# ionuc505 register map
Registers are 32-bit, access not given, no defined reset value unless marked. A register's access mark holds for its fields unless they carry their own. Addresses are absolute; registers are grouped by the start of their names; [hi:lo] are bit positions; {n}, {i} and the like mark numbered series; 'fields as' and 'values as' point back to an identical list.

## USBD
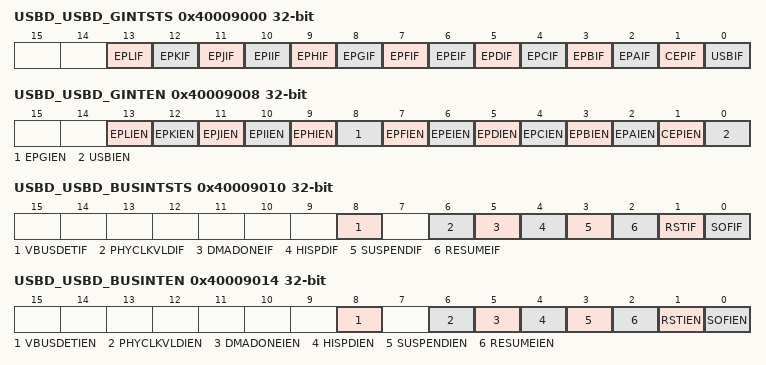
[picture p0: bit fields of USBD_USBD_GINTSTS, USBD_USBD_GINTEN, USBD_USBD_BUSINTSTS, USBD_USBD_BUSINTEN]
0x40009000 USBD_USBD_GINTSTS
  [13] EPLIF, [12] EPKIF, [11] EPJIF, [10] EPIIF, [9] EPHIF, [8] EPGIF, [7] EPFIF, [6] EPEIF, [5] EPDIF, [4] EPCIF, [3] EPBIF, [2] EPAIF, [1] CEPIF, [0] USBIF
0x40009008 USBD_USBD_GINTEN
  [13] EPLIEN, [12] EPKIEN, [11] EPJIEN, [10] EPIIEN, [9] EPHIEN, [8] EPGIEN, [7] EPFIEN, [6] EPEIEN, [5] EPDIEN, [4] EPCIEN, [3] EPBIEN, [2] EPAIEN, [1] CEPIEN, [0] USBIEN
0x40009010 USBD_USBD_BUSINTSTS
  [8] VBUSDETIF, [6] PHYCLKVLDIF, [5] DMADONEIF, [4] HISPDIF, [3] SUSPENDIF, [2] RESUMEIF, [1] RSTIF, [0] SOFIF
0x40009014 USBD_USBD_BUSINTEN
  [8] VBUSDETIEN, [6] PHYCLKVLDIEN, [5] DMADONEIEN, [4] HISPDIEN, [3] SUSPENDIEN, [2] RESUMEIEN, [1] RSTIEN, [0] SOFIEN
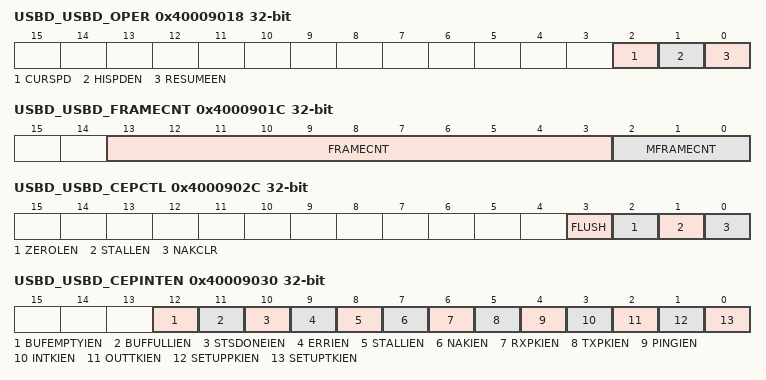
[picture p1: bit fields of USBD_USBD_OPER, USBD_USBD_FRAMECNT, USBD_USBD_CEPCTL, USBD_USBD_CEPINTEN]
0x40009018 USBD_USBD_OPER
  [2] CURSPD, [1] HISPDEN, [0] RESUMEEN
0x4000901C USBD_USBD_FRAMECNT
  [13:3] FRAMECNT, [2:0] MFRAMECNT
0x40009020 USBD_USBD_FADDR
  [6:0] FADDR
0x40009024 USBD_USBD_TEST
  [2:0] TESTMODE
0x40009028 USBD_USBD_CEPDAT
0x4000902C USBD_USBD_CEPCTL
  [3] FLUSH, [2] ZEROLEN, [1] STALLEN, [0] NAKCLR
0x40009030 USBD_USBD_CEPINTEN
  [12] BUFEMPTYIEN, [11] BUFFULLIEN, [10] STSDONEIEN, [9] ERRIEN, [8] STALLIEN, [7] NAKIEN, [6] RXPKIEN, [5] TXPKIEN, [4] PINGIEN, [3] INTKIEN, [2] OUTTKIEN, [1] SETUPPKIEN, [0] SETUPTKIEN
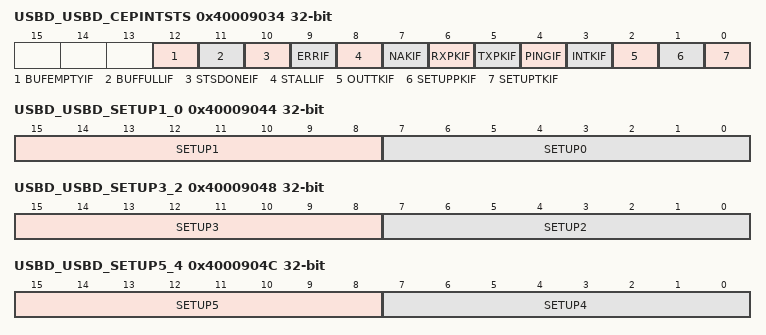
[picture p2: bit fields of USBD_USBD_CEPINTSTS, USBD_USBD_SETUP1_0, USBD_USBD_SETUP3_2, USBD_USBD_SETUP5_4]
0x40009034 USBD_USBD_CEPINTSTS
  [12] BUFEMPTYIF, [11] BUFFULLIF, [10] STSDONEIF, [9] ERRIF, [8] STALLIF, [7] NAKIF, [6] RXPKIF, [5] TXPKIF, [4] PINGIF, [3] INTKIF, [2] OUTTKIF, [1] SETUPPKIF, [0] SETUPTKIF
0x40009038 USBD_USBD_CEPTXCNT
  [7:0] TXCNT
0x4000903C USBD_USBD_CEPRXCNT
  [7:0] RXCNT
0x40009040 USBD_USBD_CEPDATCNT
  [15:0] DATCNT
0x40009044 USBD_USBD_SETUP1_0
  [15:8] SETUP1, [7:0] SETUP0
0x40009048 USBD_USBD_SETUP3_2
  [15:8] SETUP3, [7:0] SETUP2
0x4000904C USBD_USBD_SETUP5_4
  [15:8] SETUP5, [7:0] SETUP4
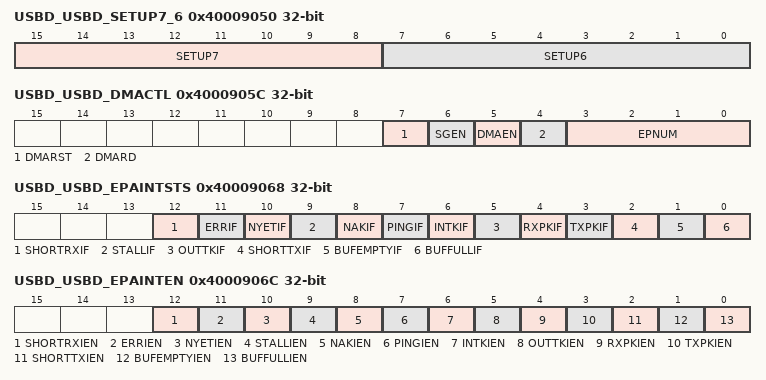
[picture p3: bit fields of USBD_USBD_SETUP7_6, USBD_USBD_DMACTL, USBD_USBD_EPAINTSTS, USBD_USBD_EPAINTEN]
0x40009050 USBD_USBD_SETUP7_6
  [15:8] SETUP7, [7:0] SETUP6
0x40009054 USBD_USBD_CEPBUFSTART
  [11:0] SADDR
0x40009058 USBD_USBD_CEPBUFEND
  [11:0] EADDR
0x4000905C USBD_USBD_DMACTL
  [7] DMARST, [6] SGEN, [5] DMAEN, [4] DMARD, [3:0] EPNUM
0x40009060 USBD_USBD_DMACNT
  [19:0] DMACNT
0x40009064 USBD_USBD_EPADAT
0x40009068 USBD_USBD_EPAINTSTS
  [12] SHORTRXIF, [11] ERRIF, [10] NYETIF, [9] STALLIF, [8] NAKIF, [7] PINGIF, [6] INTKIF, [5] OUTTKIF, [4] RXPKIF, [3] TXPKIF, [2] SHORTTXIF, [1] BUFEMPTYIF, [0] BUFFULLIF
0x4000906C USBD_USBD_EPAINTEN
  [12] SHORTRXIEN, [11] ERRIEN, [10] NYETIEN, [9] STALLIEN, [8] NAKIEN, [7] PINGIEN, [6] INTKIEN, [5] OUTTKIEN, [4] RXPKIEN, [3] TXPKIEN, [2] SHORTTXIEN, [1] BUFEMPTYIEN, [0] BUFFULLIEN
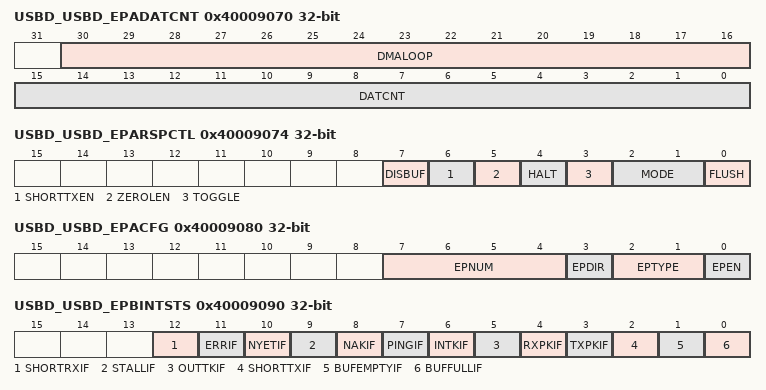
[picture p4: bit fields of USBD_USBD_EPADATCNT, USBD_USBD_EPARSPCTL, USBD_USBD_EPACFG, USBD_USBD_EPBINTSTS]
0x40009070 USBD_USBD_EPADATCNT
  [30:16] DMALOOP, [15:0] DATCNT
0x40009074 USBD_USBD_EPARSPCTL
  [7] DISBUF, [6] SHORTTXEN, [5] ZEROLEN, [4] HALT, [3] TOGGLE, [2:1] MODE, [0] FLUSH
0x40009078 USBD_USBD_EPAMPS
  [10:0] EPMPS
0x4000907C USBD_USBD_EPATXCNT
  [10:0] TXCNT
0x40009080 USBD_USBD_EPACFG
  [7:4] EPNUM, [3] EPDIR, [2:1] EPTYPE, [0] EPEN
0x40009084 USBD_USBD_EPABUFSTART
  [11:0] SADDR
0x40009088 USBD_USBD_EPABUFEND
  [11:0] EADDR
0x4000908C USBD_USBD_EPBDAT
0x40009090 USBD_USBD_EPBINTSTS
  fields as USBD_USBD_EPAINTSTS
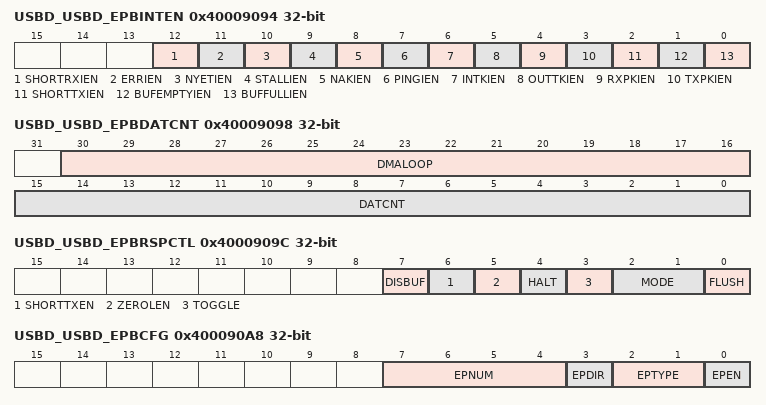
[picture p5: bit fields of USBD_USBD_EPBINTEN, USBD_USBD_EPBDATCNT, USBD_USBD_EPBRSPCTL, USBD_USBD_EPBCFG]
0x40009094 USBD_USBD_EPBINTEN
  fields as USBD_USBD_EPAINTEN
0x40009098 USBD_USBD_EPBDATCNT
  [30:16] DMALOOP, [15:0] DATCNT
0x4000909C USBD_USBD_EPBRSPCTL
  fields as USBD_USBD_EPARSPCTL
0x400090A0 USBD_USBD_EPBMPS
  [10:0] EPMPS
0x400090A4 USBD_USBD_EPBTXCNT
  [10:0] TXCNT
0x400090A8 USBD_USBD_EPBCFG
  [7:4] EPNUM, [3] EPDIR, [2:1] EPTYPE, [0] EPEN
0x400090AC USBD_USBD_EPBBUFSTART
  [11:0] SADDR
0x400090B0 USBD_USBD_EPBBUFEND
  [11:0] EADDR
0x400090B4 USBD_USBD_EPCDAT
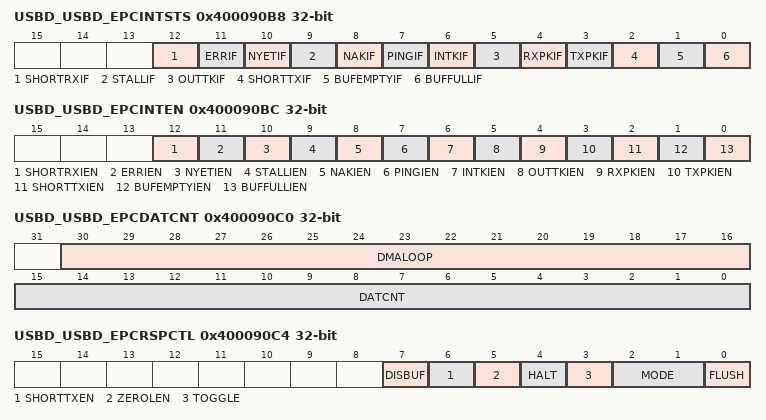
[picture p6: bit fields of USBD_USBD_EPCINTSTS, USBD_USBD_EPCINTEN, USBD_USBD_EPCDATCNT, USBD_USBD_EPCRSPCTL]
0x400090B8 USBD_USBD_EPCINTSTS
  fields as USBD_USBD_EPAINTSTS
0x400090BC USBD_USBD_EPCINTEN
  fields as USBD_USBD_EPAINTEN
0x400090C0 USBD_USBD_EPCDATCNT
  [30:16] DMALOOP, [15:0] DATCNT
0x400090C4 USBD_USBD_EPCRSPCTL
  fields as USBD_USBD_EPARSPCTL
0x400090C8 USBD_USBD_EPCMPS
  [10:0] EPMPS
0x400090CC USBD_USBD_EPCTXCNT
  [10:0] TXCNT
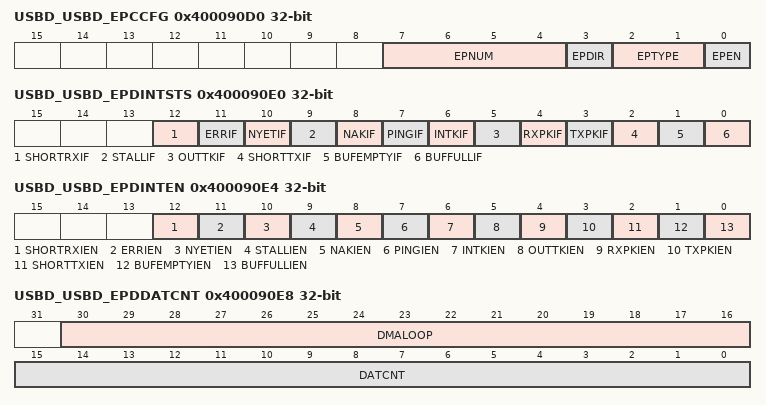
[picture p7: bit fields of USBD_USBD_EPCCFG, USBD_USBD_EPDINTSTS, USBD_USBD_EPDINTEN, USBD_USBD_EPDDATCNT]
0x400090D0 USBD_USBD_EPCCFG
  [7:4] EPNUM, [3] EPDIR, [2:1] EPTYPE, [0] EPEN
0x400090D4 USBD_USBD_EPCBUFSTART
  [11:0] SADDR
0x400090D8 USBD_USBD_EPCBUFEND
  [11:0] EADDR
0x400090DC USBD_USBD_EPDDAT
0x400090E0 USBD_USBD_EPDINTSTS
  fields as USBD_USBD_EPAINTSTS
0x400090E4 USBD_USBD_EPDINTEN
  fields as USBD_USBD_EPAINTEN
0x400090E8 USBD_USBD_EPDDATCNT
  [30:16] DMALOOP, [15:0] DATCNT
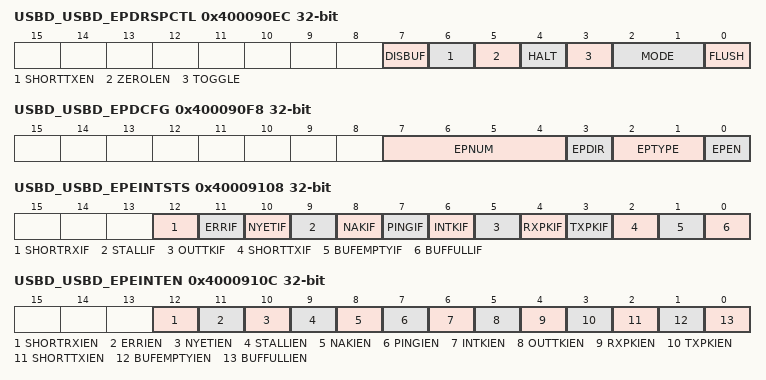
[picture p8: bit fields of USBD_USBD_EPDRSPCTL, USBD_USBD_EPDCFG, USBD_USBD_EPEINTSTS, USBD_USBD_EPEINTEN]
0x400090EC USBD_USBD_EPDRSPCTL
  fields as USBD_USBD_EPARSPCTL
0x400090F0 USBD_USBD_EPDMPS
  [10:0] EPMPS
0x400090F4 USBD_USBD_EPDTXCNT
  [10:0] TXCNT
0x400090F8 USBD_USBD_EPDCFG
  [7:4] EPNUM, [3] EPDIR, [2:1] EPTYPE, [0] EPEN
0x400090FC USBD_USBD_EPDBUFSTART
  [11:0] SADDR
0x40009100 USBD_USBD_EPDBUFEND
  [11:0] EADDR
0x40009104 USBD_USBD_EPEDAT
0x40009108 USBD_USBD_EPEINTSTS
  fields as USBD_USBD_EPAINTSTS
0x4000910C USBD_USBD_EPEINTEN
  fields as USBD_USBD_EPAINTEN
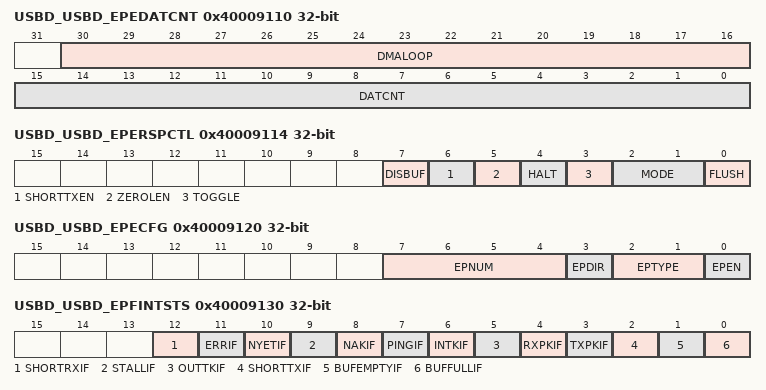
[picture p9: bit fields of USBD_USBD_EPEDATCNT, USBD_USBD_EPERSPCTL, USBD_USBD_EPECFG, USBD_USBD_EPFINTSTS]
0x40009110 USBD_USBD_EPEDATCNT
  [30:16] DMALOOP, [15:0] DATCNT
0x40009114 USBD_USBD_EPERSPCTL
  fields as USBD_USBD_EPARSPCTL
0x40009118 USBD_USBD_EPEMPS
  [10:0] EPMPS
0x4000911C USBD_USBD_EPETXCNT
  [10:0] TXCNT
0x40009120 USBD_USBD_EPECFG
  [7:4] EPNUM, [3] EPDIR, [2:1] EPTYPE, [0] EPEN
0x40009124 USBD_USBD_EPEBUFSTART
  [11:0] SADDR
0x40009128 USBD_USBD_EPEBUFEND
  [11:0] EADDR
0x4000912C USBD_USBD_EPFDAT
0x40009130 USBD_USBD_EPFINTSTS
  fields as USBD_USBD_EPAINTSTS
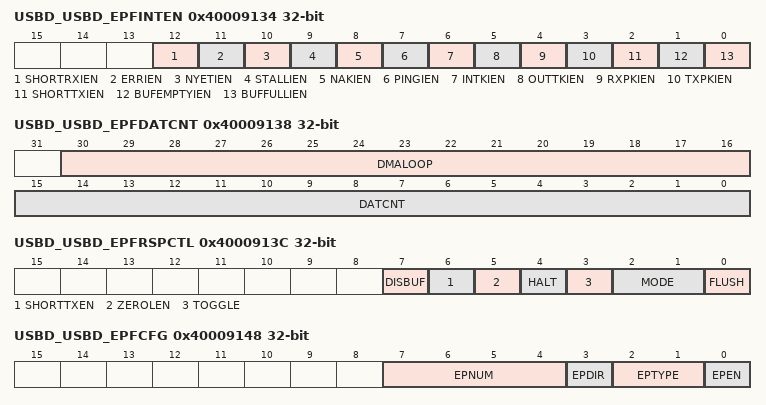
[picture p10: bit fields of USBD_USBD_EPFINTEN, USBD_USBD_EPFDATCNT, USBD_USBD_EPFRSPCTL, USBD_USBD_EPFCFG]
0x40009134 USBD_USBD_EPFINTEN
  fields as USBD_USBD_EPAINTEN
0x40009138 USBD_USBD_EPFDATCNT
  [30:16] DMALOOP, [15:0] DATCNT
0x4000913C USBD_USBD_EPFRSPCTL
  fields as USBD_USBD_EPARSPCTL
0x40009140 USBD_USBD_EPFMPS
  [10:0] EPMPS
0x40009144 USBD_USBD_EPFTXCNT
  [10:0] TXCNT
0x40009148 USBD_USBD_EPFCFG
  [7:4] EPNUM, [3] EPDIR, [2:1] EPTYPE, [0] EPEN
0x4000914C USBD_USBD_EPFBUFSTART
  [11:0] SADDR
0x40009150 USBD_USBD_EPFBUFEND
  [11:0] EADDR
0x40009154 USBD_USBD_EPGDAT
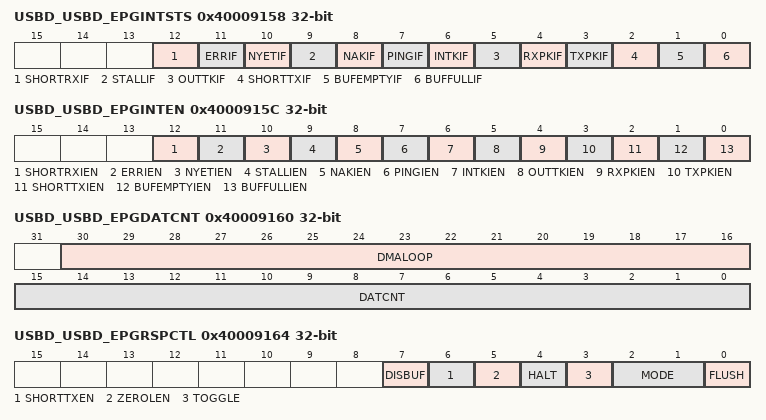
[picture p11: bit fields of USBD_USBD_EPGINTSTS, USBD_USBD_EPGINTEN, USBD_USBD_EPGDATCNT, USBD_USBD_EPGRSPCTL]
0x40009158 USBD_USBD_EPGINTSTS
  fields as USBD_USBD_EPAINTSTS
0x4000915C USBD_USBD_EPGINTEN
  fields as USBD_USBD_EPAINTEN
0x40009160 USBD_USBD_EPGDATCNT
  [30:16] DMALOOP, [15:0] DATCNT
0x40009164 USBD_USBD_EPGRSPCTL
  fields as USBD_USBD_EPARSPCTL
0x40009168 USBD_USBD_EPGMPS
  [10:0] EPMPS
0x4000916C USBD_USBD_EPGTXCNT
  [10:0] TXCNT
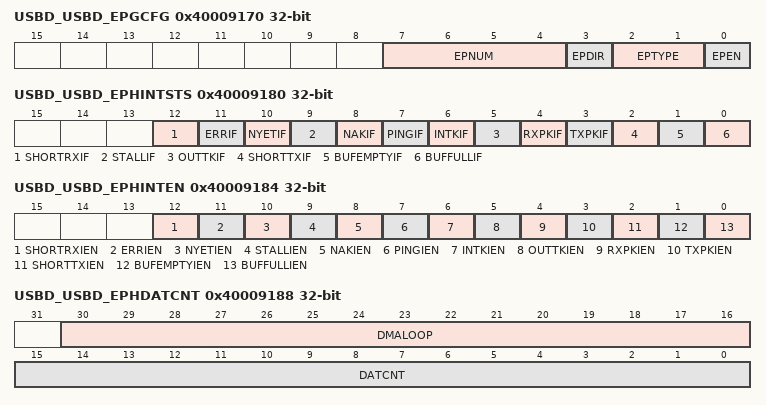
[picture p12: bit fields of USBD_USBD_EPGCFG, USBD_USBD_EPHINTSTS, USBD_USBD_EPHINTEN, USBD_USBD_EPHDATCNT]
0x40009170 USBD_USBD_EPGCFG
  [7:4] EPNUM, [3] EPDIR, [2:1] EPTYPE, [0] EPEN
0x40009174 USBD_USBD_EPGBUFSTART
  [11:0] SADDR
0x40009178 USBD_USBD_EPGBUFEND
  [11:0] EADDR
0x4000917C USBD_USBD_EPHDAT
0x40009180 USBD_USBD_EPHINTSTS
  fields as USBD_USBD_EPAINTSTS
0x40009184 USBD_USBD_EPHINTEN
  fields as USBD_USBD_EPAINTEN
0x40009188 USBD_USBD_EPHDATCNT
  [30:16] DMALOOP, [15:0] DATCNT
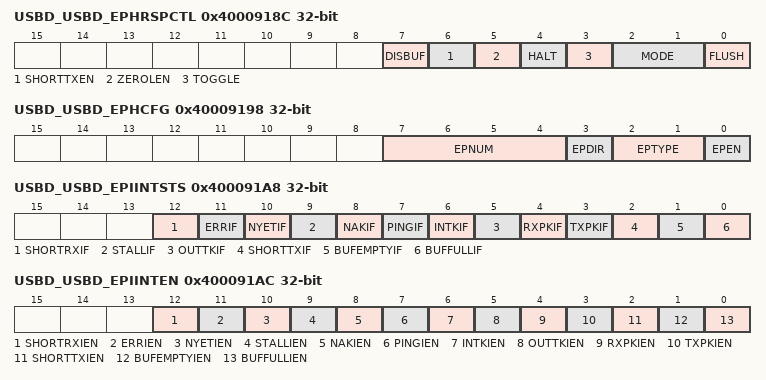
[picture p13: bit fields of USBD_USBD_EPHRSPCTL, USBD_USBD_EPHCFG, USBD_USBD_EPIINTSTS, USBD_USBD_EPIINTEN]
0x4000918C USBD_USBD_EPHRSPCTL
  fields as USBD_USBD_EPARSPCTL
0x40009190 USBD_USBD_EPHMPS
  [10:0] EPMPS
0x40009194 USBD_USBD_EPHTXCNT
  [10:0] TXCNT
0x40009198 USBD_USBD_EPHCFG
  [7:4] EPNUM, [3] EPDIR, [2:1] EPTYPE, [0] EPEN
0x4000919C USBD_USBD_EPHBUFSTART
  [11:0] SADDR
0x400091A0 USBD_USBD_EPHBUFEND
  [11:0] EADDR
0x400091A4 USBD_USBD_EPIDAT
0x400091A8 USBD_USBD_EPIINTSTS
  fields as USBD_USBD_EPAINTSTS
0x400091AC USBD_USBD_EPIINTEN
  fields as USBD_USBD_EPAINTEN
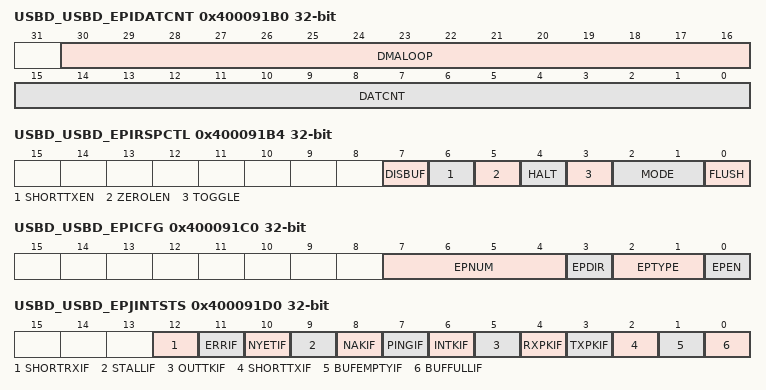
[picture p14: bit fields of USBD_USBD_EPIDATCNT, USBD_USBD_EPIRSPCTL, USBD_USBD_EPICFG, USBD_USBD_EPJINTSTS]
0x400091B0 USBD_USBD_EPIDATCNT
  [30:16] DMALOOP, [15:0] DATCNT
0x400091B4 USBD_USBD_EPIRSPCTL
  fields as USBD_USBD_EPARSPCTL
0x400091B8 USBD_USBD_EPIMPS
  [10:0] EPMPS
0x400091BC USBD_USBD_EPITXCNT
  [10:0] TXCNT
0x400091C0 USBD_USBD_EPICFG
  [7:4] EPNUM, [3] EPDIR, [2:1] EPTYPE, [0] EPEN
0x400091C4 USBD_USBD_EPIBUFSTART
  [11:0] SADDR
0x400091C8 USBD_USBD_EPIBUFEND
  [11:0] EADDR
0x400091CC USBD_USBD_EPJDAT
0x400091D0 USBD_USBD_EPJINTSTS
  fields as USBD_USBD_EPAINTSTS
0x400091D4 USBD_USBD_EPJINTEN
  fields as USBD_USBD_EPAINTEN
0x400091D8 USBD_USBD_EPJDATCNT
  [30:16] DMALOOP, [15:0] DATCNT
0x400091DC USBD_USBD_EPJRSPCTL
  fields as USBD_USBD_EPARSPCTL
0x400091E0 USBD_USBD_EPJMPS
  [10:0] EPMPS
0x400091E4 USBD_USBD_EPJTXCNT
  [10:0] TXCNT
0x400091E8 USBD_USBD_EPJCFG
  [7:4] EPNUM, [3] EPDIR, [2:1] EPTYPE, [0] EPEN
0x400091EC USBD_USBD_EPJBUFSTART
  [11:0] SADDR
0x400091F0 USBD_USBD_EPJBUFEND
  [11:0] EADDR
0x400091F4 USBD_USBD_EPKDAT
0x400091F8 USBD_USBD_EPKINTSTS
  fields as USBD_USBD_EPAINTSTS
0x400091FC USBD_USBD_EPKINTEN
  fields as USBD_USBD_EPAINTEN
0x40009200 USBD_USBD_EPKDATCNT
  [30:16] DMALOOP, [15:0] DATCNT
0x40009204 USBD_USBD_EPKRSPCTL
  fields as USBD_USBD_EPARSPCTL
0x40009208 USBD_USBD_EPKMPS
  [10:0] EPMPS
0x4000920C USBD_USBD_EPKTXCNT
  [10:0] TXCNT
0x40009210 USBD_USBD_EPKCFG
  [7:4] EPNUM, [3] EPDIR, [2:1] EPTYPE, [0] EPEN
0x40009214 USBD_USBD_EPKBUFSTART
  [11:0] SADDR
0x40009218 USBD_USBD_EPKBUFEND
  [11:0] EADDR
0x4000921C USBD_USBD_EPLDAT
0x40009220 USBD_USBD_EPLINTSTS
  fields as USBD_USBD_EPAINTSTS
0x40009224 USBD_USBD_EPLINTEN
  fields as USBD_USBD_EPAINTEN
0x40009228 USBD_USBD_EPLDATCNT
  [30:16] DMALOOP, [15:0] DATCNT
0x4000922C USBD_USBD_EPLRSPCTL
  fields as USBD_USBD_EPARSPCTL
0x40009230 USBD_USBD_EPLMPS
  [10:0] EPMPS
0x40009234 USBD_USBD_EPLTXCNT
  [10:0] TXCNT
0x40009238 USBD_USBD_EPLCFG
  [7:4] EPNUM, [3] EPDIR, [2:1] EPTYPE, [0] EPEN
0x4000923C USBD_USBD_EPLBUFSTART
  [11:0] SADDR
0x40009240 USBD_USBD_EPLBUFEND
  [11:0] EADDR
{0x40009248+4i} USBD_USBD_UVCHDAT{i} (i=0..2)
0x40009254 USBD_USBD_UVCEPAHCNT
  [3:0] CNT
0x40009258 USBD_USBD_UVCEPBHCNT
  [3:0] CNT
0x4000925C USBD_USBD_UVCEPCHCNT
  [3:0] CNT
0x40009260 USBD_USBD_UVCEPDHCNT
  [3:0] CNT
0x40009264 USBD_USBD_UVCEPEHCNT
  [3:0] CNT
0x40009268 USBD_USBD_UVCEPFHCNT
  [3:0] CNT
0x4000926C USBD_USBD_UVCEPGHCNT
  [3:0] CNT
0x40009270 USBD_USBD_UVCEPHHCNT
  [3:0] CNT
0x40009274 USBD_USBD_UVCEPIHCNT
  [3:0] CNT
0x40009278 USBD_USBD_UVCEPJHCNT
  [3:0] CNT
0x4000927C USBD_USBD_UVCEPKHCNT
  [3:0] CNT
0x40009280 USBD_USBD_UVCEPLHCNT
  [3:0] CNT
0x40009700 USBD_USBD_DMAADDR
0x40009704 USBD_USBD_PHYCTL
  [31] VBUSDET, [24] WKEN, [9] PHYEN, [8] DPPUEN
